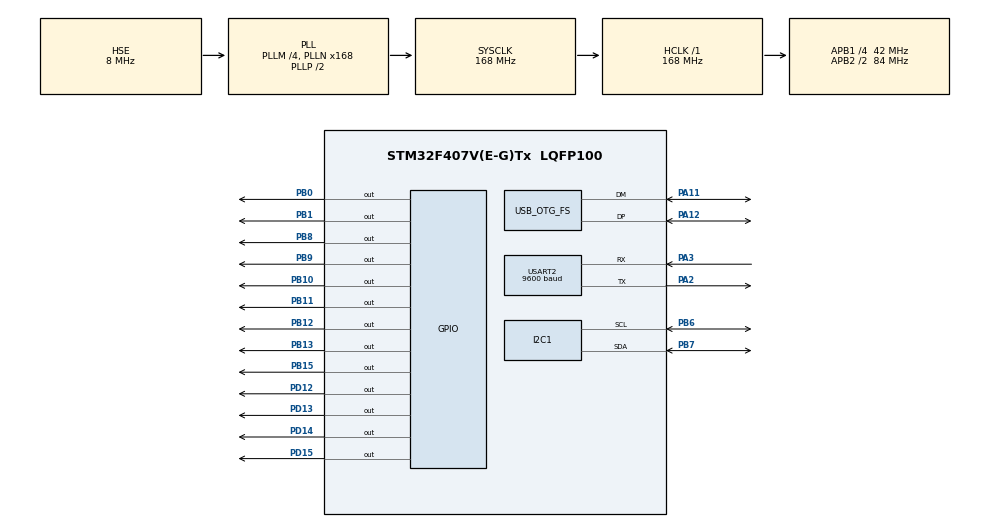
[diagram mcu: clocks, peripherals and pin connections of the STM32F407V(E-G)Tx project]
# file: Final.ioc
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FREERTOS.Tasks01=defaultTask,24,128,StartDefaultTask,Default,NULL,Dynamic,NULL,NULL
I2C1.I2C_Mode=I2C_Fast
Mcu.Family=STM32F4
Mcu.Name=STM32F407V(E-G)Tx
Mcu.Package=LQFP100
NVIC.OTG_FS_IRQn=true\:5\:0\:false\:false\:true\:true\:false\:true\:true
NVIC.PriorityGroup=NVIC_PRIORITYGROUP_4
PA11.Mode=Device_Only
PA11.Signal=USB_OTG_FS_DM
PA12.Mode=Device_Only
PA12.Signal=USB_OTG_FS_DP
PA13.Mode=Serial_Wire
PA13.Signal=SYS_JTMS-SWDIO
PA14.Mode=Serial_Wire
PA14.Signal=SYS_JTCK-SWCLK
PA2.Mode=Asynchronous
PA2.Signal=USART2_TX
PA3.Mode=Asynchronous
PA3.Signal=USART2_RX
PB0.Signal=GPIO_Output
PB1.Signal=GPIO_Output
PB10.Signal=GPIO_Output
PB11.Signal=GPIO_Output
PB12.Signal=GPIO_Output
PB13.Signal=GPIO_Output
PB15.Signal=GPIO_Output
PB6.Mode=I2C
PB6.Signal=I2C1_SCL
PB7.Mode=I2C
PB7.Signal=I2C1_SDA
PB8.Signal=GPIO_Output
PB9.Signal=GPIO_Output
PD12.Signal=GPIO_Output
PD13.Signal=GPIO_Output
PD14.Signal=GPIO_Output
PD15.Signal=GPIO_Output
PH0-OSC_IN.Mode=HSE-External-Oscillator
PH0-OSC_IN.Signal=RCC_OSC_IN
PH1-OSC_OUT.Mode=HSE-External-Oscillator
PH1-OSC_OUT.Signal=RCC_OSC_OUT
ProjectManager.HeapSize=0x200
ProjectManager.StackSize=0x400
ProjectManager.TargetToolchain=STM32CubeIDE
RCC.48MHZClocksFreq_Value=48000000
RCC.AHBFreq_Value=168000000
RCC.APB1CLKDivider=RCC_HCLK_DIV4
RCC.APB1Freq_Value=42000000
RCC.APB1TimFreq_Value=84000000
RCC.APB2CLKDivider=RCC_HCLK_DIV2
RCC.APB2Freq_Value=84000000
RCC.APB2TimFreq_Value=168000000
RCC.CortexFreq_Value=168000000
RCC.HCLKFreq_Value=168000000
RCC.HSE_VALUE=8000000
RCC.HSI_VALUE=16000000
RCC.LSE_VALUE=32768
RCC.PLLM=4
RCC.PLLN=168
RCC.PLLQ=7
RCC.SYSCLKFreq_VALUE=168000000
RCC.SYSCLKSource=RCC_SYSCLKSOURCE_PLLCLK
RCC.VCOOutputFreq_Value=336000000
USART2.BaudRate=9600
USART2.VirtualMode=VM_ASYNC
USB_DEVICE.CLASS_NAME_FS=CDC
USB_DEVICE.VirtualMode-CDC_FS=Cdc
USB_DEVICE.VirtualModeFS=Cdc_FS
USB_OTG_FS.VirtualMode=Device_Only
VP_FREERTOS_VS_CMSIS_V2.Mode=CMSIS_V2
VP_USB_DEVICE_VS_USB_DEVICE_CDC_FS.Mode=CDC_FS
board=custom

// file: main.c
/* USER CODE BEGIN Header */
/**
  ******************************************************************************
  * @file           : main.c
  * @brief          : Main program body
  ******************************************************************************
  * @attention
  *
  * Copyright (c) 2023 STMicroelectronics.
  * All rights reserved.
  *
  * This software is licensed under terms that can be found in the LICENSE file
  * in the root directory of this software component.
  * If no LICENSE file comes with this software, it is provided AS-IS.
  *
  ******************************************************************************
  */
/* USER CODE END Header */
#include "main.h"
#include "cmsis_os.h"
#include "usb_device.h"

/* USER CODE BEGIN Includes */
#include "fonts.h"         //fontlari kullanmak için
#include "ssd1306.h"       //OLED gösterge komutlarini içerir
//#include "test.h"          //test fonksyonlari için
//#include "bitmap.h"       //ege logo için
//#include "horse_anim.h"   //animasyon için
#include "stdlib.h"       // komutlari için
#include "stdio.h"       // c i/o komutlari için
#include "string.h"       // dizi komutlarini kullanmak için

/* USER CODE END Includes */

I2C_HandleTypeDef hi2c1;

UART_HandleTypeDef huart2;

/* Definitions for defaultTask */
osThreadId_t defaultTaskHandle;
const osThreadAttr_t defaultTask_attributes = {
  .name = "defaultTask",
  .stack_size = 128 * 4,
  .priority = (osPriority_t) osPriorityNormal,
};

void SystemClock_Config(void);
static void MX_GPIO_Init(void);
static void MX_USART2_UART_Init(void);
static void MX_I2C1_Init(void);
void StartDefaultTask(void *argument);

/* USER CODE BEGIN 0 */
/* RTOS object handles (defined & created in freertos.c / MX_FREERTOS_Init) */
extern osSemaphoreId_t startSem;
extern osSemaphoreId_t finishSem;
extern osSemaphoreId_t wordCountSem;
extern osMutexId_t     i2cMutex;
/* USER CODE END 0 */

int main(void)
{
    /* 1. HAL library and system clock init */
    HAL_Init();
    SystemClock_Config();

    /* 2. Initialize all configured peripherals */
    MX_GPIO_Init();
    MX_I2C1_Init();
    MX_USART2_UART_Init();
    MX_USB_DEVICE_Init();

    /* 3. Initialize the RTOS kernel */
    osKernelInitialize();

    /* 4. Create semaphores, mutex and tasks */
    MX_FREERTOS_Init();

    /* 5. Start thread execution */
    osKernelStart();

    /* We should never get here as control is now taken by the scheduler */
    while (1)
    {
    }
}

void SystemClock_Config(void)
{
  RCC_OscInitTypeDef RCC_OscInitStruct = {0};
  RCC_ClkInitTypeDef RCC_ClkInitStruct = {0};

  /** Configure the main internal regulator output voltage
  */
  __HAL_RCC_PWR_CLK_ENABLE();
  __HAL_PWR_VOLTAGESCALING_CONFIG(PWR_REGULATOR_VOLTAGE_SCALE1);

  /** Initializes the RCC Oscillators according to the specified parameters
  * in the RCC_OscInitTypeDef structure.
  */
  RCC_OscInitStruct.OscillatorType = RCC_OSCILLATORTYPE_HSE;
  RCC_OscInitStruct.HSEState = RCC_HSE_ON;
  RCC_OscInitStruct.PLL.PLLState = RCC_PLL_ON;
  RCC_OscInitStruct.PLL.PLLSource = RCC_PLLSOURCE_HSE;
  RCC_OscInitStruct.PLL.PLLM = 4;
  RCC_OscInitStruct.PLL.PLLN = 168;
  RCC_OscInitStruct.PLL.PLLP = RCC_PLLP_DIV2;
  RCC_OscInitStruct.PLL.PLLQ = 7;
  if (HAL_RCC_OscConfig(&RCC_OscInitStruct) != HAL_OK)
  {
    Error_Handler();
  }

  /** Initializes the CPU, AHB and APB buses clocks
  */
  RCC_ClkInitStruct.ClockType = RCC_CLOCKTYPE_HCLK|RCC_CLOCKTYPE_SYSCLK
                              |RCC_CLOCKTYPE_PCLK1|RCC_CLOCKTYPE_PCLK2;
  RCC_ClkInitStruct.SYSCLKSource = RCC_SYSCLKSOURCE_PLLCLK;
  RCC_ClkInitStruct.AHBCLKDivider = RCC_SYSCLK_DIV1;
  RCC_ClkInitStruct.APB1CLKDivider = RCC_HCLK_DIV4;
  RCC_ClkInitStruct.APB2CLKDivider = RCC_HCLK_DIV2;

  if (HAL_RCC_ClockConfig(&RCC_ClkInitStruct, FLASH_LATENCY_5) != HAL_OK)
  {
    Error_Handler();
  }
}

static void MX_I2C1_Init(void)
{

  hi2c1.Instance = I2C1;
  hi2c1.Init.ClockSpeed = 400000;
  hi2c1.Init.DutyCycle = I2C_DUTYCYCLE_2;
  hi2c1.Init.OwnAddress1 = 0;
  hi2c1.Init.AddressingMode = I2C_ADDRESSINGMODE_7BIT;
  hi2c1.Init.DualAddressMode = I2C_DUALADDRESS_DISABLE;
  hi2c1.Init.OwnAddress2 = 0;
  hi2c1.Init.GeneralCallMode = I2C_GENERALCALL_DISABLE;
  hi2c1.Init.NoStretchMode = I2C_NOSTRETCH_DISABLE;
  if (HAL_I2C_Init(&hi2c1) != HAL_OK)
  {
    Error_Handler();
  }

}

static void MX_USART2_UART_Init(void)
{

  huart2.Instance = USART2;
  huart2.Init.BaudRate = 9600;
  huart2.Init.WordLength = UART_WORDLENGTH_8B;
  huart2.Init.StopBits = UART_STOPBITS_1;
  huart2.Init.Parity = UART_PARITY_NONE;
  huart2.Init.Mode = UART_MODE_TX_RX;
  huart2.Init.HwFlowCtl = UART_HWCONTROL_NONE;
  huart2.Init.OverSampling = UART_OVERSAMPLING_16;
  if (HAL_UART_Init(&huart2) != HAL_OK)
  {
    Error_Handler();
  }

}

static void MX_GPIO_Init(void)
{
  GPIO_InitTypeDef GPIO_InitStruct = {0};

  /* GPIO Ports Clock Enable */
  __HAL_RCC_GPIOH_CLK_ENABLE();
  __HAL_RCC_GPIOA_CLK_ENABLE();
  __HAL_RCC_GPIOB_CLK_ENABLE();
  __HAL_RCC_GPIOD_CLK_ENABLE();

  /*Configure GPIO pin Output Level */
  HAL_GPIO_WritePin(GPIOB, GPIO_PIN_0|GPIO_PIN_1|GPIO_PIN_10|GPIO_PIN_11
                          |GPIO_PIN_12|GPIO_PIN_13|GPIO_PIN_15|GPIO_PIN_8
                          |GPIO_PIN_9, GPIO_PIN_RESET);

  /*Configure GPIO pin Output Level */
  HAL_GPIO_WritePin(GPIOD, GPIO_PIN_12|GPIO_PIN_13|GPIO_PIN_14|GPIO_PIN_15, GPIO_PIN_RESET);

  /*Configure GPIO pins : PB0 PB1 PB10 PB11
                           PB12 PB13 PB15 PB8
                           PB9 */
  GPIO_InitStruct.Pin = GPIO_PIN_0|GPIO_PIN_1|GPIO_PIN_10|GPIO_PIN_11
                          |GPIO_PIN_12|GPIO_PIN_13|GPIO_PIN_15|GPIO_PIN_8
                          |GPIO_PIN_9;
  GPIO_InitStruct.Mode = GPIO_MODE_OUTPUT_PP;
  GPIO_InitStruct.Pull = GPIO_NOPULL;
  GPIO_InitStruct.Speed = GPIO_SPEED_FREQ_LOW;
  HAL_GPIO_Init(GPIOB, &GPIO_InitStruct);

  /*Configure GPIO pins : PD12 PD13 PD14 PD15 */
  GPIO_InitStruct.Pin = GPIO_PIN_12|GPIO_PIN_13|GPIO_PIN_14|GPIO_PIN_15;
  GPIO_InitStruct.Mode = GPIO_MODE_OUTPUT_PP;
  GPIO_InitStruct.Pull = GPIO_NOPULL;
  GPIO_InitStruct.Speed = GPIO_SPEED_FREQ_LOW;
  HAL_GPIO_Init(GPIOD, &GPIO_InitStruct);

}

void StartDefaultTask(void *argument)
{
  /* init code for USB_DEVICE */
  MX_USB_DEVICE_Init();
  for(;;)
  {
    osDelay(1);
  }
}

void Error_Handler(void)
{
  __disable_irq();
  while (1)
  {
  }
}

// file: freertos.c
/* freertos.c */

#include "FreeRTOS.h"
#include "task.h"
#include "cmsis_os2.h"
#include "main.h"         // pulls in stm32f4xx_hal.h and GPIO_PIN_x/GPIOB defs
#include "ssd1306.h"      // SSD1306_COLOR_BLACK, SSD1306_* APIs
#include "fonts.h"        // Font_11x18, Font_16x26
#include <stdio.h>        // snprintf
#include <string.h>       // memcpy, strncmp
#include <ctype.h>        // isdigit
#include "usbd_cdc_if.h"

#define SEGMENT_COUNT 7
#define DIGIT_COUNT   2

static const uint16_t segmentPins[SEGMENT_COUNT] = {
  GPIO_PIN_8, GPIO_PIN_9, GPIO_PIN_10,
  GPIO_PIN_11, GPIO_PIN_12, GPIO_PIN_13, GPIO_PIN_14
};

static const uint16_t digitPins[DIGIT_COUNT] = {
  GPIO_PIN_0, GPIO_PIN_1
};

static const uint8_t digitPatterns[10][SEGMENT_COUNT] = {
  {1,1,1,1,1,1,0}, {0,1,1,0,0,0,0}, {1,1,0,1,1,0,1},
  {1,1,1,1,0,0,1}, {0,1,1,0,0,1,1}, {1,0,1,1,0,1,1},
  {1,0,1,1,1,1,1}, {1,1,1,0,0,0,0}, {1,1,1,1,1,1,1},
  {1,1,1,1,0,1,1}
};

void displayDigit(uint8_t digit, uint8_t position)
{
  for (uint8_t i = 0; i < SEGMENT_COUNT; ++i) {
    HAL_GPIO_WritePin(GPIOB, segmentPins[i], GPIO_PIN_RESET);
  }
  for (uint8_t i = 0; i < DIGIT_COUNT; ++i) {
    HAL_GPIO_WritePin(GPIOB, digitPins[i], GPIO_PIN_RESET);
  }
  for (uint8_t i = 0; i < SEGMENT_COUNT; ++i) {
    HAL_GPIO_WritePin(GPIOB, segmentPins[i],
                      digitPatterns[digit][i] ? GPIO_PIN_SET : GPIO_PIN_RESET);
  }
  HAL_GPIO_WritePin(GPIOB, digitPins[position], GPIO_PIN_SET);
}

extern void CountdownTask(void *argument);
extern void DisplayTask(void *argument);
extern void displayDigit(uint8_t digit, uint8_t position);

void CountdownTask(void *argument);
void DisplayTask  (void *argument);

/* semafor ve mutex handle’ları (main.h ya da freertos.h içinde extern tanımlı olmalı) */
osSemaphoreId_t startSem;
osSemaphoreId_t finishSem;
osSemaphoreId_t wordCountSem;
osMutexId_t     i2cMutex;

extern uint32_t trueWordCount;
extern char CDC_Buffer[64];

void DisplayTask(void *argument) {
  (void)argument;
  char buf[24];
  for (;;) {
    /* geri sayım bitti semaforünü bekle */
    osSemaphoreAcquire(finishSem, osWaitForever);
    char numStr[12];                                         // 4 294 967 295 + '\0'
    snprintf(numStr, sizeof(numStr), "%lu", (unsigned long)trueWordCount);
    /* doğru kelime sayısını oku */
    //uint32_t total = osSemaphoreGetCount(finishCountSem);

    /* ekrana yaz */
    /* trueWordCount = uint32_t  → %lu veya %u  */
    printf("%lu\r\n", (unsigned long)trueWordCount);
    snprintf(buf, sizeof(buf), "True Words: %u", (unsigned int)trueWordCount);
    osMutexAcquire(i2cMutex, osWaitForever);
    SSD1306_Fill(SSD1306_COLOR_BLACK);
    SSD1306_GotoXY(0,0);
    SSD1306_Puts(buf, &Font_11x18, 1);
    /* --- 2) Sayı  (alt satır, ortalanmış) --------------------------- */
    uint8_t digits = strlen(numStr);                         // kaç rakam?
    uint8_t pxWidth = digits * 16;                           // 16x26 → 16 px genişlik
    uint8_t startX  = (128 - pxWidth) / 2;                   // yatay merkezle

    SSD1306_GotoXY(startX, 26);                              // y = 18+4 padding ≈ 26
    SSD1306_Puts(numStr, &Font_16x26, 1);
    SSD1306_UpdateScreen();
    osMutexRelease(i2cMutex);
  }
}

void CountdownTask(void *argument) {
  (void)argument;
  for (;;) {
    /* “begin” komutu gelene kadar bekle */
    osSemaphoreAcquire(startSem, osWaitForever);

    /* OLED’e “Start!” yaz */
    osMutexAcquire(i2cMutex, osWaitForever);
    SSD1306_Init();
    SSD1306_Fill(SSD1306_COLOR_BLACK);
    SSD1306_GotoXY(20,20);
    SSD1306_Puts("Start!", &Font_16x26, 1);
    SSD1306_UpdateScreen();
    osMutexRelease(i2cMutex);

    /* 30’dan 0’a geri sayım */
    for (int cnt = 30; cnt >= 0; --cnt) {
      uint8_t tens = cnt / 10;
      uint8_t ones = cnt % 10;
      /* multiplex display için kısmi beklemelerle */
      for (int i = 0; i < 50; ++i) {
        osMutexAcquire(i2cMutex, osWaitForever);
        displayDigit(tens, 0);
        osDelay(10);
        displayDigit(ones, 1);
        osDelay(10);
        osMutexRelease(i2cMutex);

      }
    }

    /* geri sayım bitti, DisplayTask’a haber ver */
    osSemaphoreRelease(finishSem);
  }
}

void MX_FREERTOS_Init(void) {

  /* Create the semaphores */
  startSem = osSemaphoreNew(
      1,    /* max count */
      0,    /* initial count = 0, bekletecek */
      NULL  /* attr */);
  finishSem = osSemaphoreNew(1, 0, NULL);
  wordCountSem = osSemaphoreNew(
      100,  /* max count = en fazla 100 “give”’i tutabilir */
      0,    /* initial = 0 */
      NULL);
  /* Create the mutex for I²C/OLED/7-seg */
  i2cMutex = osMutexNew(NULL);

  /* Create the threads */
  const osThreadAttr_t cntdAttrs = {
      .name = "CntdTask",
      .priority = (osPriority_t) osPriorityNormal,
      .stack_size = 512
  };
  osThreadNew(CountdownTask, NULL, &cntdAttrs);

  const osThreadAttr_t dispAttrs = {
      .name = "DispTask",
      .priority = (osPriority_t) osPriorityLow,
      .stack_size = 512
  };
  osThreadNew(DisplayTask, NULL, &dispAttrs);

  /* USER CODE BEGIN RTOS_THREADS */
  /* burada ek görevler ekleyebilirsiniz */
  /* USER CODE END RTOS_THREADS */
}
